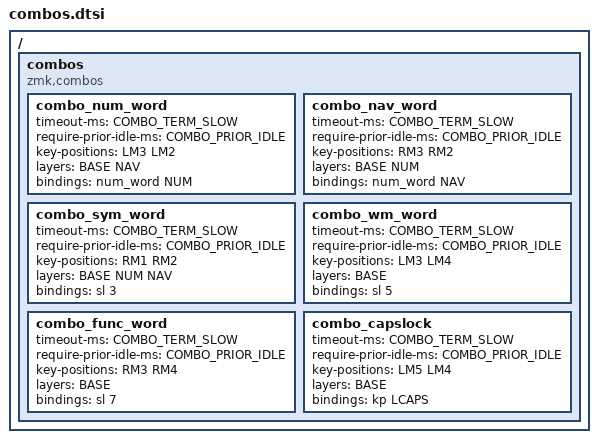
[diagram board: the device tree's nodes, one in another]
/*
 *	Use this file for your combos
 */

/* Horizontal combos - left hand */
ZMK_COMBO(mouse, &smart_mouse, LM1 LM2,     BASE NAV NUM, COMBO_TERM_FAST, COMBO_IDLE_FAST)

/ {
  combos {
    compatible = "zmk,combos";

    combo_num_word {
      timeout-ms = <COMBO_TERM_SLOW>;
      require-prior-idle-ms = <COMBO_PRIOR_IDLE>;
      key-positions = <LM3 LM2>;
      layers = <BASE NAV>;
      bindings = <&num_word NUM>;
    };
    combo_nav_word {
      timeout-ms = <COMBO_TERM_SLOW>;
      require-prior-idle-ms = <COMBO_PRIOR_IDLE>;
      key-positions = <RM3 RM2>;
      layers = <BASE NUM>;
      bindings = <&num_word NAV>;
    };
    combo_sym_word {
      timeout-ms = <COMBO_TERM_SLOW>;
      require-prior-idle-ms = <COMBO_PRIOR_IDLE>;
      key-positions = <RM1 RM2>;
      layers = <BASE NUM NAV>;
      bindings = <&sl 3>;
    };
    combo_wm_word {
      timeout-ms = <COMBO_TERM_SLOW>;
      require-prior-idle-ms = <COMBO_PRIOR_IDLE>;
      key-positions = <LM3 LM4>;
      layers = <BASE>;
      bindings = <&sl 5>;
    };
    combo_func_word {
      timeout-ms = <COMBO_TERM_SLOW>;
      require-prior-idle-ms = <COMBO_PRIOR_IDLE>;
      key-positions = <RM3 RM4>;
      layers = <BASE>;
      bindings = <&sl 7>;
    };
    combo_capslock {
      timeout-ms = <COMBO_TERM_SLOW>;
      require-prior-idle-ms = <COMBO_PRIOR_IDLE>;
      key-positions = <LM5 LM4>;
      layers = <BASE>;
      bindings = <&kp LCAPS>;
    };
  };
};
